# G32R501 register map
Vendor: Geehy Semiconductor Co., Ltd.; Series: G32R5; File version: 1.0
CPU: CM55 r0p1, little endian, MPU, FPU, double-precision FPU, DSP, VTOR, 4 interrupt priority bits
Registers are 32-bit, read-write, reset 0x0 unless marked. A register's access mark holds for its fields unless they carry their own. Offsets are from the block's base; [hi:lo] are bit positions; {n}, {i} and the like mark numbered series.

## AS — Analog Subsystem (AS)
Base 0x50028000
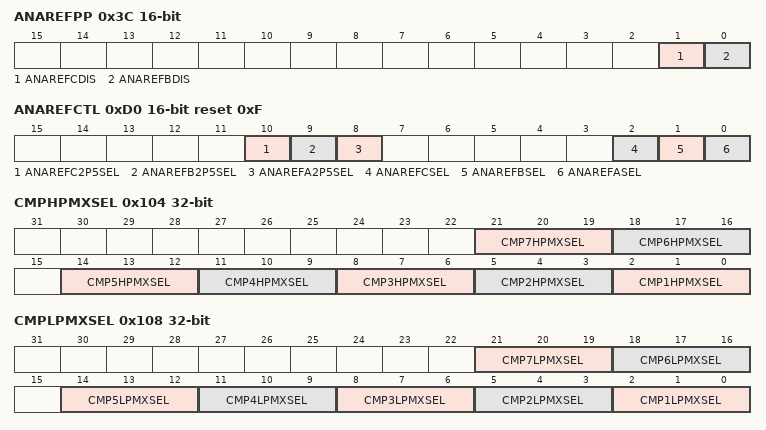
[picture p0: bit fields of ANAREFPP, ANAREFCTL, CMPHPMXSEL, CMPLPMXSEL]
0x3C ANAREFPP 16-bit — ADC Analog Reference Peripheral Properties register
  [1] ANAREFCDIS — AREFC Disable
  [0] ANAREFBDIS — AREFB Disable
0xC0 TSNSCTL 16-bit — Temperature Sensor Control Register
  [0] ENABLE — Temperature Sensor Enable
0xD0 ANAREFCTL 16-bit reset 0xF — Analog Reference Control Register
  [10] ANAREFC2P5SEL — Analog reference C 2.5V source select
  [9] ANAREFB2P5SEL — Analog reference B 2.5V source select
  [8] ANAREFA2P5SEL — Analog reference A 2.5V source select
  [2] ANAREFCSEL — Analog reference C mode select
  [1] ANAREFBSEL — Analog reference B mode select
  [0] ANAREFASEL — Analog reference A mode select
0xE0 VMONCTL 16-bit — Voltage Monitor Control Register
  [8] BORLDIS — BORL disable on VDDIO
0x104 CMPHPMXSEL
  [21:19] CMP7HPMXSEL — Select source on the COMP7_HP input
  [18:16] CMP6HPMXSEL — Select source on the COMP6_HP input
  [3n-1:3n-3] CMP{n}HPMXSEL (n=1..5) — Select source on the COMP{n}_HP input
0x108 CMPLPMXSEL
  [21:19] CMP7LPMXSEL — Select source on the COMP7_LP input
  [18:16] CMP6LPMXSEL — Select source on the COMP6_LP input
  [3n-1:3n-3] CMP{n}LPMXSEL (n=1..5) — Select source on the COMP{n}_LP input
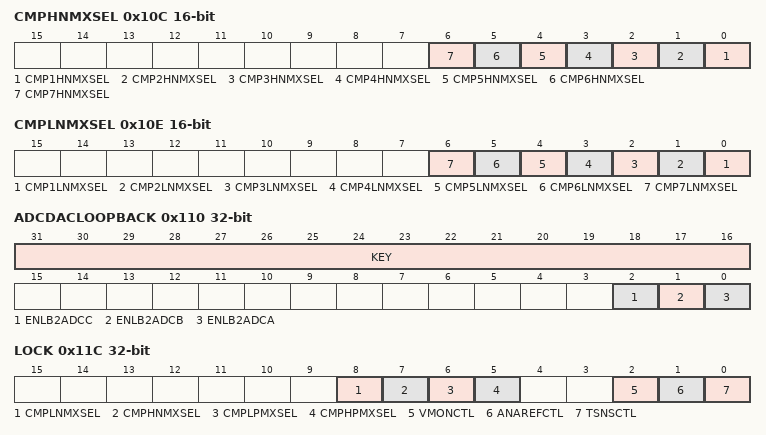
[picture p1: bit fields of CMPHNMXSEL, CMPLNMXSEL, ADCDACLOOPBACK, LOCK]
0x10C CMPHNMXSEL 16-bit
  [n-1] CMP{n}HNMXSEL (n=1..7) — Select source on the COMP{n}_HN input
0x10E CMPLNMXSEL 16-bit
  [n-1] CMP{n}LNMXSEL (n=1..7) — Select source on the COMP{n}_LN input
0x110 ADCDACLOOPBACK — Enabble loopback from DAC to ADCs
  [31:16] KEY
  [2] ENLB2ADCC — Loopback COMPDACA output to ADCC
  [1] ENLB2ADCB — Loopback COMPDACA output to ADCB
  [0] ENLB2ADCA — Loopback COMPDACA output to ADCA
0x11C LOCK
  [8] CMPLNMXSEL — AS_COMPLNMXSEL Register Lock
  [7] CMPHNMXSEL — AS_COMPHNMXSEL Register Lock
  [6] CMPLPMXSEL — AS_COMPLPMXSEL Register Lock
  [5] CMPHPMXSEL — AS_COMPHPMXSEL Register Lock
  [2] VMONCTL — AS_VMCTRL Register Lock
  [1] ANAREFCTL — AREFCTRL Register Lock
  [0] TSNSCTL — AS_TSCTRL Register Lock

## DCS_B0Z1 — Dual Code Security for BANK0 Zone1
Base 0x50024000
0x00 B0Z1LP ro reset 0xFFFFFFFF
  [28:0] POINTER — Zone 1 Link Pointer for flash BANK0
0x04 Z1_OTPSECLOCK ro reset 0xFFF
  [7:4] PSWDLOCK — CS password locations lock
0x08 Z1_BOOTDEF_HIGH ro reset 0xFFFFFFFF
  [31:0] BOOTDEFH — Boot definition high
0x0C B0Z1LPERR ro
  [28:0] POINTERERR — Link Pointer error for flash BANK0
0x10 Z1_BOOTPIN_CONFIG ro reset 0xFFFFFFFF
  [31:0] BOOTPINCFG — Boot Pin Configuration
0x14 Z1_GPREG2 ro reset 0xFFFFFFFF
  [31:0] GENPUR — General Purpose Register 2
0x18 Z1_BOOTDEF_LOW ro reset 0xFFFFFFFF
  [31:0] BOOTDEFL — Boot definition Low
0x20 Z1CSKEY0
  [31:0] CSKEY0 — Zone 1 CSM Key 0
0x24 Z1CSKEY1 ro
  [31:0] CSKEY1 — Zone 1 CSM Key 1
0x28 Z1CSKEY2 ro
  [31:0] CSKEY2 — Zone 1 CSM Key 2
0x2C Z1CSKEY3
  [31:0] CSKEY3 — Zone 1 CSM Key 3
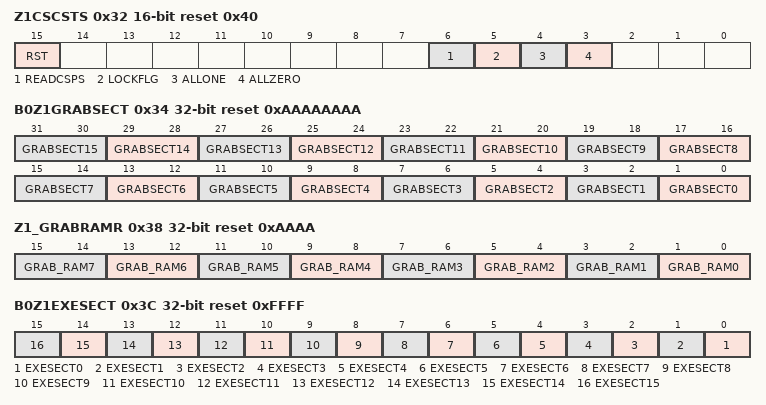
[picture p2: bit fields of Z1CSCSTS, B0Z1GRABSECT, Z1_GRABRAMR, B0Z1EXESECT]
0x32 Z1CSCSTS 16-bit reset 0x40
  [15] RST — Zone1 reset
  [6] READCSPS ro — Read CS password locations
  [5] LOCKFLG ro — Zone1 lock flag
  [4] ALLONE ro — CS Passwords are all one flag
  [3] ALLZERO ro — CS Passwords are all zero flag
0x34 B0Z1GRABSECT ro reset 0xAAAAAAAA
  [2n+1:2n] GRABSECT{n} (n=0..15) — Zone 1 Grab Flash BANK0 Sectors x configuration
0x38 Z1_GRABRAMR ro reset 0xAAAA
  [2n+1:2n] GRAB_RAM{n} (n=0..7) — Zone 1 Grab RAMx configuration
0x3C B0Z1EXESECT ro reset 0xFFFF
  [n] EXESECT{n} (n=0..15) — Zone 1 Flash BANK0 Sector x Execute_Only disabled
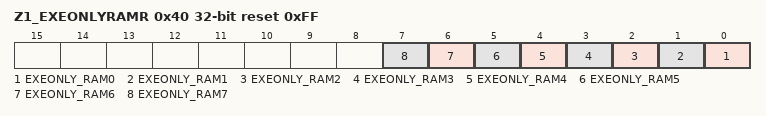
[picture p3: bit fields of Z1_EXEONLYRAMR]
0x40 Z1_EXEONLYRAMR ro reset 0xFF
  [n] EXEONLY_RAM{n} (n=0..7) — Zone 1 RAMx Execute_Only disabled

## DCS_B0Z2 — Dual Code Security for BANK0 Zone2
Base 0x50024080
0x00 B0Z2LP ro reset 0xFFFFFFFF
  [28:0] POINTER — Zone 2 Link Pointer for flash BANK0
0x04 Z2_OTPSECLOCK ro reset 0xFFF
  [7:4] PSWDLOCK — CS password locations lock
0x0C B0Z2LPERR ro
  [28:0] POINTERERR — Link Pointer error for flash BANK0
0x20 Z2CSKEY0 ro
  [31:0] CSKEY0 — Zone 2 CSM Key 0
{0x20+4i} Z2CSKEY{i} (i=1..3)
  [31:0] CSKEY{i} — Zone 2 CSM Key {i}
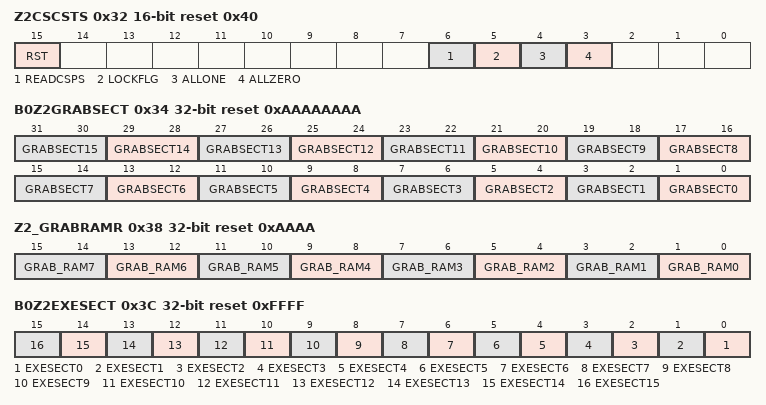
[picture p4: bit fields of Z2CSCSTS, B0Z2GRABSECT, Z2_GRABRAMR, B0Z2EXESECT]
0x32 Z2CSCSTS 16-bit reset 0x40
  [15] RST — Zone2 reset
  [6] READCSPS ro — Read CS password locations
  [5] LOCKFLG ro — Zone1 lock flag
  [4] ALLONE ro — CS Passwords are all one flag
  [3] ALLZERO ro — CS Passwords are all zero flag
0x34 B0Z2GRABSECT ro reset 0xAAAAAAAA
  [2n+1:2n] GRABSECT{n} (n=0..15) — Zone 2 Grab Flash BANK0 Sectors x configuration
0x38 Z2_GRABRAMR ro reset 0xAAAA
  [2n+1:2n] GRAB_RAM{n} (n=0..7) — Zone 2 Grab RAMx configuration
0x3C B0Z2EXESECT ro reset 0xFFFF
  [n] EXESECT{n} (n=0..15) — Zone 2 Flash BANK0 Sector x Execute_Only disabled
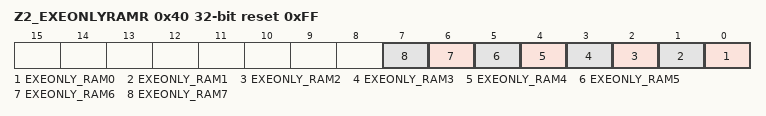
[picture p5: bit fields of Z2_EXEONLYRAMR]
0x40 Z2_EXEONLYRAMR ro reset 0xFF
  [n] EXEONLY_RAM{n} (n=0..7) — Zone 2 RAMx Execute_Only disabled
